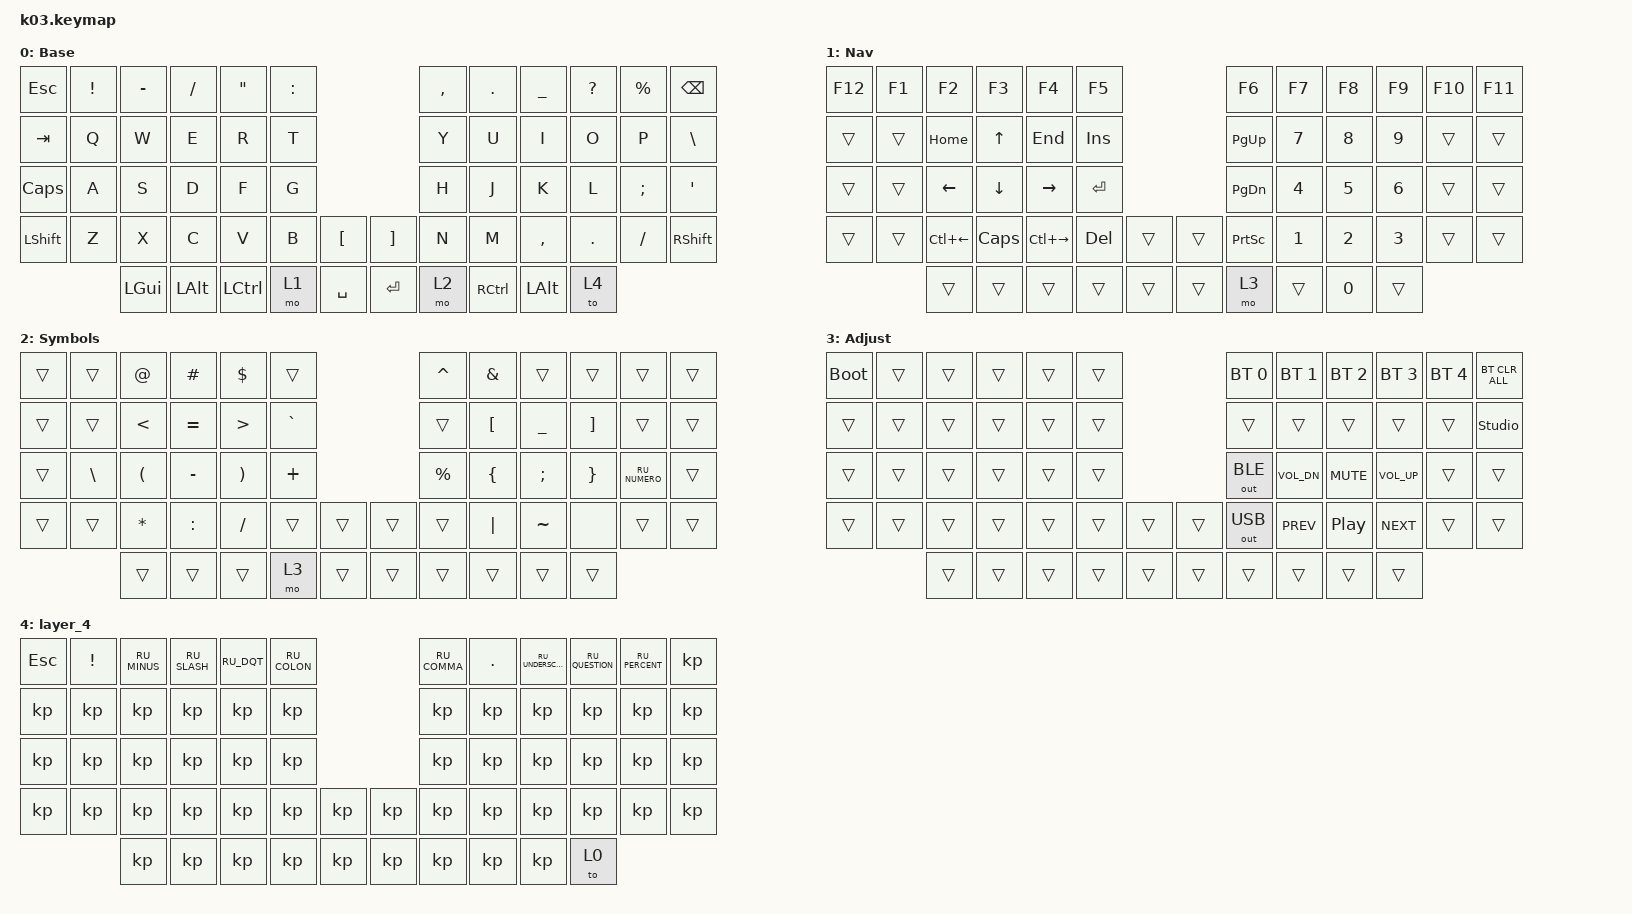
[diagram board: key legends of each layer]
#include "keys_ru.h"
#include <behaviors.dtsi>
#include <dt-bindings/zmk/bt.h>
#include <dt-bindings/zmk/keys.h>
#include <dt-bindings/zmk/outputs.h>

/ {
    behaviors {
        enc_vol: enc_vol {
            compatible = "zmk,behavior-sensor-rotate";
            label = "ENC_VOL";
            #sensor-binding-cells = <0>;
            bindings = <&kp C_VOL_UP>, <&kp C_VOL_DN>;
        };
    };

    keymap {
        compatible = "zmk,keymap";

        base {
            bindings = <
&kp ESC       &kp EXCL  &kp MINUS  &kp FSLH  &kp DOUBLE_QUOTES  &kp COLON                          &kp COMMA  &kp DOT    &kp UNDERSCORE  &kp QUESTION  &kp PERCENT  &kp BSPC
&kp TAB       &kp Q     &kp W      &kp E     &kp R              &kp T                              &kp Y      &kp U      &kp I           &kp O         &kp P        &kp BSLH
&kp CAPSLOCK  &kp A     &kp S      &kp D     &kp F              &kp G                              &kp H      &kp J      &kp K           &kp L         &kp SEMI     &kp SQT
&kp LSHFT     &kp Z     &kp X      &kp C     &kp V              &kp B      &kp LBKT     &kp RBKT   &kp N      &kp M      &kp COMMA       &kp DOT       &kp FSLH     &kp RSHFT
                        &kp LGUI   &kp LALT  &kp LCTRL          &mo 1      &kp SPACE    &kp ENTER  &mo 2      &kp RCTRL  &kp LALT        &to 4
            >;

            display-name = "Base";
            sensor-bindings =
                <&enc_vol>,
                <&enc_vol>,
                <&enc_vol>,
                <&enc_vol>,
                <&enc_vol>,
                <&enc_vol>;
        };

        nav {
            bindings = <
&kp F12  &kp F1  &kp F2        &kp F3    &kp F4         &kp F5                     &kp F6           &kp F7  &kp F8  &kp F9  &kp F10  &kp F11
&trans   &trans  &kp HOME      &kp UP    &kp END        &kp INS                    &kp PG_UP        &kp N7  &kp N8  &kp N9  &trans   &trans
&trans   &trans  &kp LEFT      &kp DOWN  &kp RIGHT      &kp RET                    &kp PG_DN        &kp N4  &kp N5  &kp N6  &trans   &trans
&trans   &trans  &kp LC(LEFT)  &kp CAPS  &kp LC(RIGHT)  &kp DEL  &trans    &trans  &kp PRINTSCREEN  &kp N1  &kp N2  &kp N3  &trans   &trans
                 &trans        &trans    &trans         &trans   &trans    &trans  &mo 3            &trans  &kp N0  &trans
            >;

            display-name = "Nav";
        };

        sym {
            bindings = <
&trans  &trans    &kp AT    &kp HASH   &kp DOLLAR  &trans                       &kp CARET  &kp AMPS  &trans     &trans    &trans         &trans
&trans  &trans    &kp LT    &kp EQUAL  &kp GT      &kp GRAVE                    &trans     &kp LBKT  &kp UNDER  &kp RBKT  &trans         &trans
&trans  &kp BSLH  &kp LPAR  &kp MINUS  &kp RPAR    &kp PLUS                     &kp PRCNT  &kp LBRC  &kp SEMI   &kp RBRC  &kp RU_NUMERO  &trans
&trans  &trans    &kp STAR  &kp COLON  &kp FSLH    &trans     &trans    &trans  &trans     &kp PIPE  &kp TILDE  &none     &trans         &trans
                  &trans    &trans     &trans      &mo 3      &trans    &trans  &trans     &trans    &trans     &trans
            >;

            display-name = "Symbols";
        };

        adj {
            bindings = <
&bootloader  &trans  &trans  &trans  &trans  &trans                    &bt BT_SEL 0  &bt BT_SEL 1  &bt BT_SEL 2      &bt BT_SEL 3  &bt BT_SEL 4  &bt BT_CLR_ALL
&trans       &trans  &trans  &trans  &trans  &trans                    &trans        &trans        &trans            &trans        &trans        &studio_unlock
&trans       &trans  &trans  &trans  &trans  &trans                    &out OUT_BLE  &kp C_VOL_DN  &kp C_MUTE        &kp C_VOL_UP  &trans        &trans
&trans       &trans  &trans  &trans  &trans  &trans  &trans    &trans  &out OUT_USB  &kp C_PREV    &kp C_PLAY_PAUSE  &kp C_NEXT    &trans        &trans
                     &trans  &trans  &trans  &trans  &trans    &trans  &trans        &trans        &trans            &trans
            >;

            display-name = "Adjust";
        };

        layer_4 {
            bindings = <
&kp ESC  &kp EXCL  &kp RU_MINUS  &kp RU_SLASH  &kp RU_DQT  &kp RU_COLON              &kp RU_COMMA  &kp DOT  &kp RU_UNDERSCORE  &kp RU_QUESTION  &kp RU_PERCENT  &kp
&kp      &kp       &kp           &kp           &kp         &kp                       &kp           &kp      &kp                &kp              &kp             &kp
&kp      &kp       &kp           &kp           &kp         &kp                       &kp           &kp      &kp                &kp              &kp             &kp
&kp      &kp       &kp           &kp           &kp         &kp           &kp    &kp  &kp           &kp      &kp                &kp              &kp             &kp
                   &kp           &kp           &kp         &kp           &kp    &kp  &kp           &kp      &kp                &to 0
            >;
        };
    };
};
